# myChip register map
Vendor: ARM Ltd.; Series: ARMCM3; File version: 1.2
CPU: CM3 r2p1, little endian, no MPU, no FPU, 3 interrupt priority bits
Registers are 32-bit, read-write, reset 0x0 unless marked. A register's access mark holds for its fields unless they carry their own. Offsets are from the block's base; [hi:lo] are bit positions; {n}, {i} and the like mark numbered series; 'fields as' and 'values as' point back to an identical list.

## DAC0
Base 0x40039000
Same registers: DAC{n} {0x40039000+0x100*n} (n=1..8)
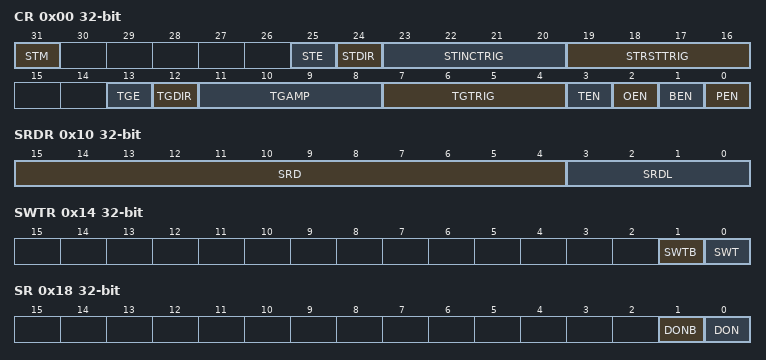
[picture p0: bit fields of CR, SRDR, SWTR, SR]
0x00 CR — DACx Config Register
  [31] STM — 锯齿波更新模式位
  [25] STE — 锯齿波产生使能位
  [24] STDIR — 锯齿波步进方向选择位
  [23:20] STINCTRIG — 锯齿波步进触发源选择位
  [19:16] STRSTTRIG — 锯齿波复位触发源选择位
  [13] TGE — 三角波产生使能位
  [12] TGDIR — 三角波起始方向选择
  [11:8] TGAMP — 三角波增长最大幅度选择位
  [7:4] TGTRIG — 三角波触发源选择位
  [3] TEN — DAC触发转换使能位
  [2] OEN — DAC Buffer输出使能位
  [1] BEN — DAC Bypass Buffer输出使能位
  [0] PEN — DAC使能位
0x04 WDR — DACx Write Data Register
  [11:0] WDAT — DAC写入输出数据
0x08 RDR — DACx Read Data Register
  [11:0] RDAT ro — DAC读取输出数据
0x0C SIDR — DACx Sawtooth Increment Register
  [15:0] SID — DAC锯齿波形增量数据
0x10 SRDR — DACx Sawtooth Reset Register
  [15:4] SRD — DAC锯齿波形复位数据
  [3:0] SRDL ro — DAC锯齿波形输出数据
0x14 SWTR — DACx Software Trigger Register
  [1] SWTB — DAC 软件触发SWTB事件
  [0] SWT — DAC 软件触发SWT事件
0x18 SR — DACx Status Register
  [1] DONB — DAC DONB标志位
  [0] DON — DAC DON中断标志位

## CORDIC
Base 0x4003F000
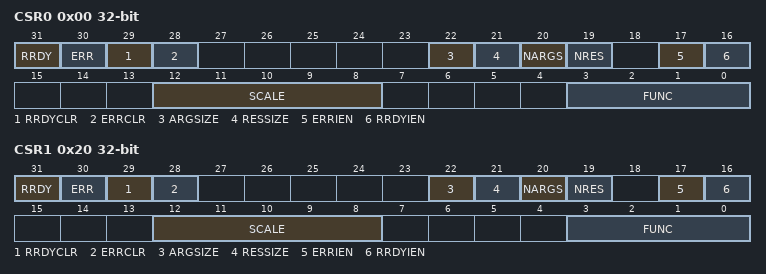
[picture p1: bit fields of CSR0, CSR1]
0x00 CSR0 — CORDIC Control / Status register0
  [31] RRDY ro — 计算结果完成中断状态（Result Ready Interrupt Status）
  [30] ERR ro — 错误中断状态（Error Interrupt Status）
  [29] RRDYCLR — 计算结果完成中断清除（Result Ready Interrupt Clear）
  [28] ERRCLR — 错误中断清除（Error Interrupt Clear）
  [22] ARGSIZE — 输入数据的宽度（Input Argument Size）
  [21] RESSIZE — 输出数据的宽度（Output Result Size）
  [20] NARGS — 输入数据的个数（Input Argument Number）
  [19] NRES — 输出数据的个数(Output Result Number）
  [17] ERRIEN — 错误中断使能（Error Interrupt Enable）
  [16] RRDYIEN — 计算结果完成中断使能（Result Ready Interrupt Enable）
  [12:8] SCALE — CORDIC比例因子设置（CORDIC Scale Setting）
  [3:0] FUNC — CORDIC计算的函数（CORDIC Calculation Function）
0x04 ARX0 — CORDIC Argument / Result register0
  [31:0] ARGRESX — 数据寄存器X（Argument/Result Data Register X）
0x08 ARY0 — CORDIC Argument / Result register0
  [31:0] ARGRESY — 数据寄存器Y（Argument/Result Data Register Y）
0x20 CSR1 — CORDIC Control / Status register1
  fields as CSR0
0x24 ARX1 — CORDIC Argument / Result register1
  [31:0] ARGRESX — 数据寄存器X（Argument/Result Data Register X）
0x28 ARY1 — CORDIC Argument / Result register1
  [31:0] ARGRESY — 数据寄存器Y（Argument/Result Data Register Y）

## CMP0
Base 0x4003A000
Same registers: CMP{n} {0x4003A000+0x100*n} (n=1..8)
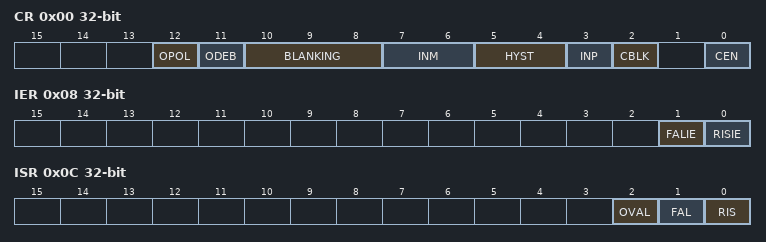
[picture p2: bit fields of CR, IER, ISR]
0x00 CR — CMPx Config Register
  [12] OPOL — 比较输出极性选择
  [11] ODEB — 比较输出同步选择
  [10:8] BLANKING — 比较消隐事件选择
  [7:6] INM — 比较负端源选择
  [5:4] HYST — 比较迟滞
  [3] INP — 比较正端源选择
  [2] CBLK — 软件消隐选择
  [0] CEN — 比较使能
0x04 DEBR — CMPx Debounce Register
  [7:0] DEB — 比较输出消抖值
0x08 IER — CMPx Interrupt Enable Register
  [1] FALIE — 比较下降沿中断使能
  [0] RISIE — 比较上升沿中断使能
0x0C ISR — CMPx Interrupt Status Register
  [2] OVAL ro — 比较输出状态
  [1] FAL — 比较下降沿中断标志位
  [0] RIS — 比较上升沿中断标志位

## TMR7
Base 0x40008000
Same registers: TMR8 0x40009000
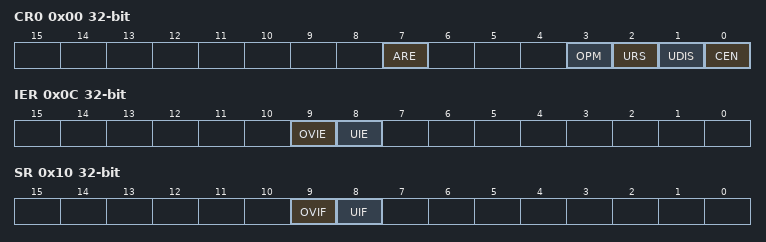
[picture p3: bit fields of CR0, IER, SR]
0x00 CR0 — TMRx Control Register0
  [7] ARE — 自动重载使能(AutoReload Enable)
  [3] OPM — 单脉冲模式(One Pulse Mode)
  [2] URS — 更新事件源(Update Request Source)
  [1] UDIS — 更新禁止位(Update Disable)
  [0] CEN — 计数器使能位(Counter Enable)
0x04 CR1 — TMRx Control Register1
  [1:0] MMS — 主模式选择(Master Mode Selection)
0x0C IER — TMRx Interrupt Enable Register
  [9] OVIE — 计数上溢中断使能(Overflow Interrupt Enable)
  [8] UIE — 更新中断使能(Update Interrupt Enable)
0x10 SR — TMRx Status Register
  [9] OVIF — 计数器上溢中断标志位(Counter Overflow Interrupt Flag)
  [8] UIF — 更新中断标志(Update Interrupt Flag)
0x14 UGR — TMRx Update Generation Register
  [0] UG — 更新事件生成(Update Generation)：
0x2C TCR — TMRx Trigger Control Register
  [3:0] TOW — TRGO脉冲宽度控制(Trigger Output Width)
0x30 CPR — TMRx Counter Period Register
  [15:0] CPV — 计数周期值(Counter Period Value)
0x38 PSCR — TMRx Prescaler Register
  [15:0] PSC — 预分频寄存器（Prescaler Value)
0x3C CNTR — TMRx Counter Register
  [15:0] CNT — 定时器计数值(Counter Value)

## TMR6
Base 0x4000E000
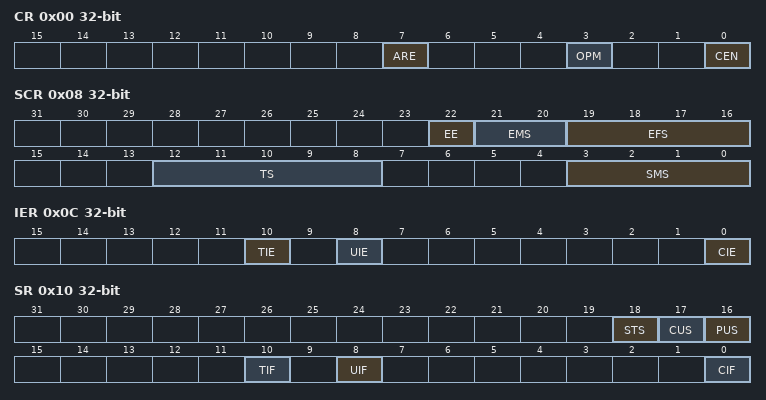
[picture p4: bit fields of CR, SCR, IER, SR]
0x00 CR — TMRx Control Register
  [7] ARE — 自动重载使能(AutoReload Enable)
  [3] OPM — 单脉冲模式(One Pulse Mode)
  [0] CEN — 定时器使能位(Timer Enable)
0x08 SCR — TMRx Slave Control Register
  [22] EE — ETR模式选择(ETR Mode Selection)
  [21:20] EMS — ETR模式选择(ETR Mode Selection)
  [19:16] EFS — ETR滤波选择(ETR Filter Selection)
  [12:8] TS — 触发选择(Trigger Selection)
  [3:0] SMS — 从模式选择(Slave Mode Selection)
0x0C IER — TMRx Interrupt Enable Register
  [10] TIE — 触发中断使能(Trigger Interrupt Enable)
  [8] UIE — 更新中断使能(Update Interrupt Enable)
  [0] CIE — 比较中断使能(Compare Interrupt Enable)
0x10 SR — TMRx Status Register
  [18] STS ro — 计数器状态标志（Counter Running Status）
  [17] CUS ro — 比较值更新标志（Compare Update Status）
  [16] PUS ro — 周期值更新标志（Period Update Status）
  [10] TIF — 触发中断标志(Trigger Interrupt Flag)
  [8] UIF — 更新中断标志(Update Interrupt Flag)
  [0] CIF — 比较成功中断标志位(Compare Interrupt Flag)
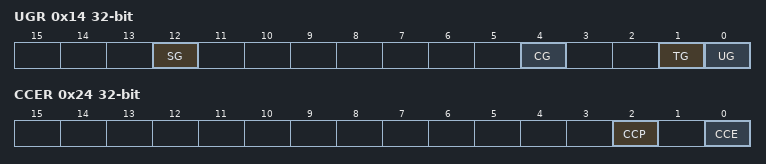
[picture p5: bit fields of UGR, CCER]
0x14 UGR — TMRx Update Generation Register
  [12] SG — 计数器启动事件生成(Counter Start Generation)
  [4] CG — 比较更新事件生成(Compare Update Generation)
  [1] TG — 触发事件生成(Trigger Generation)
  [0] UG — 更新事件生成(Update Generation)
0x20 CCMR — TMRx Compare Mode Register
  [2] RLD — 比较自动加载使能(Compare Auto-Realod Enable)
0x24 CCER — TMRx Compare Enable Register
  [2] CCP — 比较极性选择(Compare Polarity)
  [0] CCE — 比较通道使能(Compare Enable)
0x30 CPR — TMRx Counter Period Register
  [15:0] CPV — 计数周期值(Counter Period Value)
0x38 PSCR — TMRx Prescaler Register
  [7:0] PSC — 预分频寄存器（Prescaler Value)
0x3C CNTR — TMRx Counter Register
  [15:0] CNT ro — 定时器计数值(Counter Value)
0x50 CC0R — TMRx Compare Register
  [15:0] CMP — 输出比较值(Compare Value)
